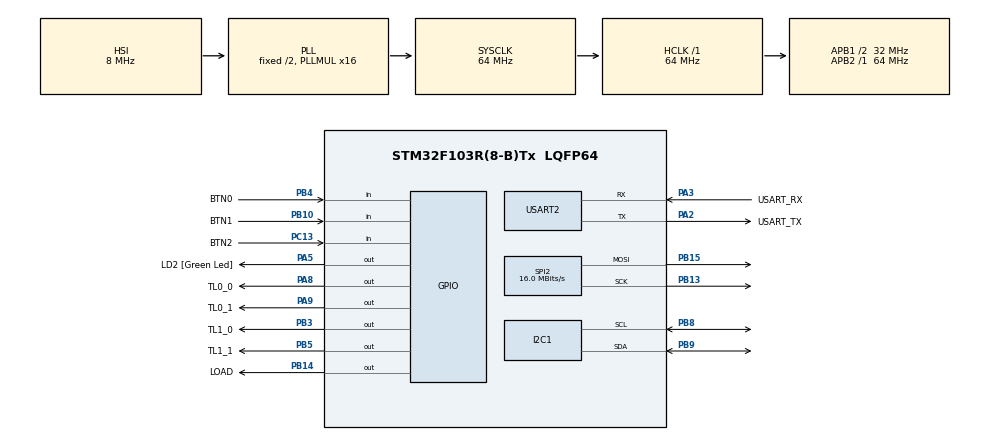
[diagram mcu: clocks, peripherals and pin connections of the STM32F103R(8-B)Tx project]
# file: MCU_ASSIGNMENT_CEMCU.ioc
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Dma.I2C1_RX.0.Direction=DMA_PERIPH_TO_MEMORY
Dma.I2C1_RX.0.Instance=DMA1_Channel7
Dma.I2C1_RX.0.MemDataAlignment=DMA_MDATAALIGN_BYTE
Dma.I2C1_RX.0.MemInc=DMA_MINC_ENABLE
Dma.I2C1_RX.0.Mode=DMA_NORMAL
Dma.I2C1_RX.0.PeriphDataAlignment=DMA_PDATAALIGN_BYTE
Dma.I2C1_RX.0.PeriphInc=DMA_PINC_DISABLE
Dma.I2C1_RX.0.Priority=DMA_PRIORITY_LOW
Dma.I2C1_TX.1.Direction=DMA_MEMORY_TO_PERIPH
Dma.I2C1_TX.1.Instance=DMA1_Channel6
Dma.I2C1_TX.1.MemDataAlignment=DMA_MDATAALIGN_BYTE
Dma.I2C1_TX.1.MemInc=DMA_MINC_ENABLE
Dma.I2C1_TX.1.Mode=DMA_NORMAL
Dma.I2C1_TX.1.PeriphDataAlignment=DMA_PDATAALIGN_BYTE
Dma.I2C1_TX.1.PeriphInc=DMA_PINC_DISABLE
Dma.I2C1_TX.1.Priority=DMA_PRIORITY_LOW
Dma.Request0=I2C1_RX
Dma.Request1=I2C1_TX
Mcu.Family=STM32F1
Mcu.Name=STM32F103R(8-B)Tx
Mcu.Package=LQFP64
NVIC.DMA1_Channel6_IRQn=true\:0\:0\:false\:false\:true\:false\:true\:true
NVIC.DMA1_Channel7_IRQn=true\:0\:0\:false\:false\:true\:false\:true\:true
NVIC.I2C1_ER_IRQn=true\:0\:0\:false\:false\:true\:true\:true\:true
NVIC.I2C1_EV_IRQn=true\:0\:0\:false\:false\:true\:true\:true\:true
NVIC.PriorityGroup=NVIC_PRIORITYGROUP_4
NVIC.SPI2_IRQn=true\:0\:0\:false\:false\:true\:true\:true\:true
NVIC.TIM3_IRQn=true\:0\:0\:false\:false\:true\:true\:true\:true
PA13.Signal=SYS_JTMS-SWDIO
PA14.GPIO_Label=TCK
PA14.Signal=SYS_JTCK-SWCLK
PA2.GPIO_Label=USART_TX
PA2.GPIO_Mode=GPIO_MODE_AF_PP
PA2.GPIO_PuPd=GPIO_NOPULL
PA2.GPIO_Speed=GPIO_SPEED_FREQ_LOW
PA2.Mode=Asynchronous
PA2.Signal=USART2_TX
PA3.GPIO_Label=USART_RX
PA3.GPIO_Mode=GPIO_MODE_AF_PP
PA3.GPIO_PuPd=GPIO_NOPULL
PA3.GPIO_Speed=GPIO_SPEED_FREQ_LOW
PA3.Mode=Asynchronous
PA3.Signal=USART2_RX
PA5.GPIO_Label=LD2 [Green Led]
PA5.GPIO_ModeDefaultOutputPP=GPIO_MODE_OUTPUT_PP
PA5.GPIO_PuPd=GPIO_NOPULL
PA5.GPIO_Speed=GPIO_SPEED_FREQ_LOW
PA5.Signal=GPIO_Output
PA8.GPIO_Label=TL0_0
PA8.Signal=GPIO_Output
PA9.GPIO_Label=TL0_1
PA9.Signal=GPIO_Output
PB10.GPIO_Label=BTN1
PB10.Signal=GPIO_Input
PB13.Mode=TX_Only_Simplex_Unidirect_Master
PB13.Signal=SPI2_SCK
PB14.GPIO_Label=LOAD
PB14.Signal=GPIO_Output
PB15.Mode=TX_Only_Simplex_Unidirect_Master
PB15.Signal=SPI2_MOSI
PB3.GPIO_Label=TL1_0
PB3.Signal=GPIO_Output
PB4.GPIO_Label=BTN0
PB4.Signal=GPIO_Input
PB5.GPIO_Label=TL1_1
PB5.Signal=GPIO_Output
PB8.Mode=I2C
PB8.Signal=I2C1_SCL
PB9.Mode=I2C
PB9.Signal=I2C1_SDA
PC13-TAMPER-RTC.GPIO_Label=BTN2
PC13-TAMPER-RTC.Signal=GPIO_Input
PC14-OSC32_IN.Mode=LSE-External-Oscillator
PC14-OSC32_IN.Signal=RCC_OSC32_IN
PC15-OSC32_OUT.Mode=LSE-External-Oscillator
PC15-OSC32_OUT.Signal=RCC_OSC32_OUT
PD0-OSC_IN.Mode=HSE-External-Clock-Source
PD0-OSC_IN.Signal=RCC_OSC_IN
PD1-OSC_OUT.Mode=HSE-External-Clock-Source
PD1-OSC_OUT.Signal=RCC_OSC_OUT
ProjectManager.HeapSize=0x200
ProjectManager.StackSize=0x400
ProjectManager.TargetToolchain=STM32CubeIDE
RCC.AHBFreq_Value=64000000
RCC.APB1CLKDivider=RCC_HCLK_DIV2
RCC.APB1Freq_Value=32000000
RCC.APB1TimFreq_Value=64000000
RCC.APB2Freq_Value=64000000
RCC.APB2TimFreq_Value=64000000
RCC.HCLKFreq_Value=64000000
RCC.PLLMUL=RCC_PLL_MUL16
RCC.RTCClockSelection=RCC_RTCCLKSOURCE_LSE
RCC.SYSCLKFreq_VALUE=64000000
RCC.SYSCLKSource=RCC_SYSCLKSOURCE_PLLCLK
RCC.USBFreq_Value=64000000
SPI2.CalculateBaudRate=16.0 MBits/s
SPI2.Direction=SPI_DIRECTION_2LINES
SPI2.Mode=SPI_MODE_MASTER
SPI2.VirtualType=VM_MASTER
TIM3.Period=99
TIM3.Prescaler=639
USART2.VirtualMode=VM_ASYNC
VP_SYS_VS_ND.Mode=No_Debug
VP_TIM3_VS_ClockSourceINT.Mode=Internal
board=NUCLEO-F103RB

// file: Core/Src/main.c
/* USER CODE BEGIN Header */
/**
  ******************************************************************************
  * @file           : main.c
  * @brief          : Main program body
  ******************************************************************************
  * @attention
  *
  * Copyright (c) 2025 STMicroelectronics.
  * All rights reserved.
  *
  * This software is licensed under terms that can be found in the LICENSE file
  * in the root directory of this software component.
  * If no LICENSE file comes with this software, it is provided AS-IS.
  *
  ******************************************************************************
  */
/* USER CODE END Header */
#include "main.h"
#include "dma.h"
#include "i2c.h"
#include "spi.h"
#include "tim.h"
#include "usart.h"
#include "gpio.h"

/* USER CODE BEGIN Includes */
#include "global.h"
#include "scheduler.h"
#include "tasks.h"
#include "i2c-lcd.h"
/* USER CODE END Includes */

void SystemClock_Config(void);

int main(void)
{

  /* MCU Configuration--------------------------------------------------------*/

  /* Reset of all peripherals, Initializes the Flash interface and the Systick. */
  HAL_Init();

  /* Configure the system clock */
  SystemClock_Config();

  /* Initialize all configured peripherals */
  MX_GPIO_Init();
  MX_DMA_Init();
  MX_USART2_UART_Init();
  MX_I2C1_Init();
  MX_TIM3_Init();
  MX_SPI2_Init();
  /* USER CODE BEGIN 2 */
  lcd_init();
  lcd_clear_display();
  traffic_light_status = INIT;

  HAL_TIM_Base_Start_IT(&htim3);

  SCH_Add_Task(task_timer_run, 0, 1);

  SCH_Add_Task(task_toggle_status_led, 1000, 1000);
  SCH_Add_Task(task_traffic_light_fsm, 100, 10);
  /* USER CODE END 2 */

  /* Infinite loop */
  while (1)
  {
	  SCH_Dispatch_Tasks();
  }
}

void SystemClock_Config(void)
{
  RCC_OscInitTypeDef RCC_OscInitStruct = {0};
  RCC_ClkInitTypeDef RCC_ClkInitStruct = {0};

  /** Initializes the RCC Oscillators according to the specified parameters
  * in the RCC_OscInitTypeDef structure.
  */
  RCC_OscInitStruct.OscillatorType = RCC_OSCILLATORTYPE_HSI;
  RCC_OscInitStruct.HSIState = RCC_HSI_ON;
  RCC_OscInitStruct.HSICalibrationValue = RCC_HSICALIBRATION_DEFAULT;
  RCC_OscInitStruct.PLL.PLLState = RCC_PLL_ON;
  RCC_OscInitStruct.PLL.PLLSource = RCC_PLLSOURCE_HSI_DIV2;
  RCC_OscInitStruct.PLL.PLLMUL = RCC_PLL_MUL16;
  if (HAL_RCC_OscConfig(&RCC_OscInitStruct) != HAL_OK)
  {
    Error_Handler();
  }

  /** Initializes the CPU, AHB and APB buses clocks
  */
  RCC_ClkInitStruct.ClockType = RCC_CLOCKTYPE_HCLK|RCC_CLOCKTYPE_SYSCLK
                              |RCC_CLOCKTYPE_PCLK1|RCC_CLOCKTYPE_PCLK2;
  RCC_ClkInitStruct.SYSCLKSource = RCC_SYSCLKSOURCE_PLLCLK;
  RCC_ClkInitStruct.AHBCLKDivider = RCC_SYSCLK_DIV1;
  RCC_ClkInitStruct.APB1CLKDivider = RCC_HCLK_DIV2;
  RCC_ClkInitStruct.APB2CLKDivider = RCC_HCLK_DIV1;

  if (HAL_RCC_ClockConfig(&RCC_ClkInitStruct, FLASH_LATENCY_2) != HAL_OK)
  {
    Error_Handler();
  }
}

/* USER CODE BEGIN 4 */
void HAL_TIM_PeriodElapsedCallback (TIM_HandleTypeDef *htim) {
	SCH_Update();
}
/* USER CODE END 4 */

void Error_Handler(void)
{
  __disable_irq();
  while (1)
  {
  }
}
